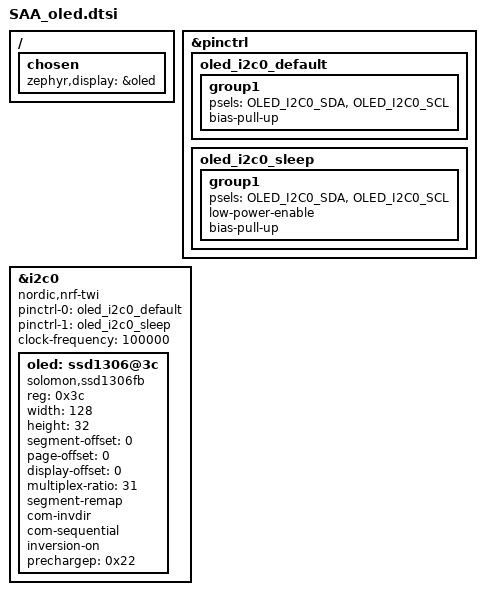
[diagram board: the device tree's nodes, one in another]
/ {
	chosen {
		zephyr,display = &oled;
	};
};

&pinctrl {
	oled_i2c0_default: oled_i2c0_default {
		group1 {
			psels = <OLED_I2C0_SDA>,
				<OLED_I2C0_SCL>;
			bias-pull-up;
		};
	};

	oled_i2c0_sleep: oled_i2c0_sleep {
		group1 {
			psels = <OLED_I2C0_SDA>,
				<OLED_I2C0_SCL>;
			low-power-enable;
			bias-pull-up;
		};
	};
};

&i2c0 {
	status = "okay";
	compatible = "nordic,nrf-twi";
	pinctrl-0 = <&oled_i2c0_default>;
	pinctrl-1 = <&oled_i2c0_sleep>;
	pinctrl-names = "default", "sleep";
	clock-frequency = <100000>;

	oled: ssd1306@3c {
		compatible = "solomon,ssd1306fb";
		reg = <0x3c>;
		width = <128>;
		height = <32>;
		segment-offset = <0>;
		page-offset = <0>;
		display-offset = <0>;
		multiplex-ratio = <31>;
		segment-remap;
		com-invdir;
		com-sequential;
		inversion-on;
		prechargep = <0x22>;
	};
};
